# MSP430FR5962 register map
File version: 2.1
CPU: MSP430FR5962 r2p1, little endian, MPU, no FPU, 3 interrupt priority bits
Registers are 16-bit, read-write, reset 0x0 unless marked. A register's access mark holds for its fields unless they carry their own. Offsets are from the block's base; [hi:lo] are bit positions; {n}, {i} and the like mark numbered series; 'fields as' and 'values as' point back to an identical list.

## PJ
Base 0x00000200
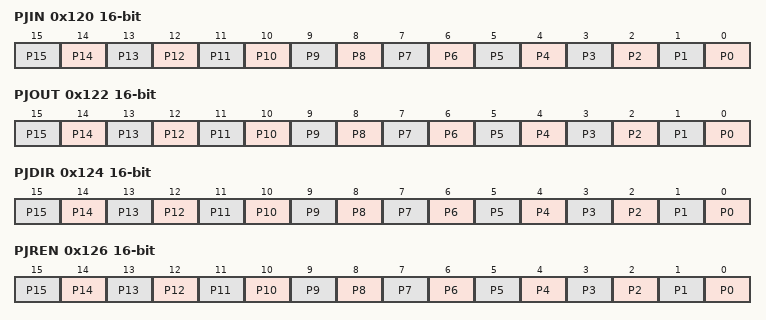
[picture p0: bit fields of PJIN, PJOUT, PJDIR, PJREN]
0x120 PJIN — Port J Input
  [n] P{n} (n=0..15)
0x122 PJOUT — Port J Output
  [n] P{n} (n=0..15)
0x124 PJDIR — Port J Direction
  [n] P{n} (n=0..15)
0x126 PJREN — Port J Resistor Enable
  [n] P{n} (n=0..15)
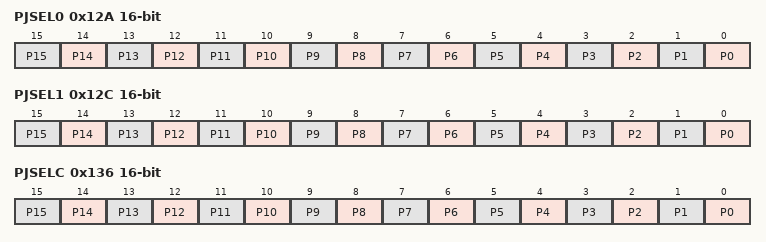
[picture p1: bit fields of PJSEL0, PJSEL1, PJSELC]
0x12A PJSEL0 — Port J Select 0
  [n] P{n} (n=0..15)
0x12C PJSEL1 — Port J Select 1
  [n] P{n} (n=0..15)
0x136 PJSELC — Port J Complement Select
  [n] P{n} (n=0..15)

## DMA
Base 0x00000500
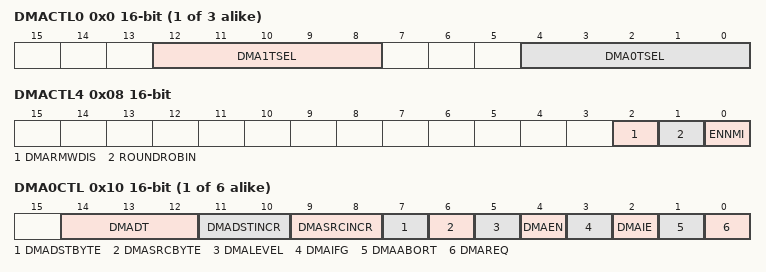
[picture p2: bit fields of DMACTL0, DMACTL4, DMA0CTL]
{0x0+2i} DMACTL{i} (i=0..2) — DMA Control {i}
  [12:8] DMA{2i+1}TSEL — [12:8] DMA trigger select
    {v}=DMA{2i+1}TRIG{v} (v=0..31)
  [4:0] DMA{2i}TSEL — [4:0] DMA trigger select
    {v}=DMA{2i}TRIG{v} (v=0..31)
0x08 DMACTL4 — DMA Control 4
  [2] DMARMWDIS — [2:2] Read-modify-write disable
    0=DMA transfers can occur during read-modify-write CPU operations; 1=DMA transfers inhibited during read-modify-write CPU operations
  [1] ROUNDROBIN — [1:1] Round robin
    0=DMA channel priority is DMA0-DMA1-DMA2 - ... - DMA7; 1=DMA channel priority changes with each transfer
  [0] ENNMI — [0:0] Enable NMI
    0=NMI does not interrupt DMA transfer; 1=NMI interrupts a DMA transfer
0x0E DMAIV — DMA Interrupt Vector
  [15:0] DMAIV — [15:0] DMA interrupt vector value
    0=NONE (No interrupt pending); 2=DMA0IFG (Interrupt Source: DMA channel 0; Interrupt Flag: DMA0IFG; Interrupt Priority: Highest); 4=DMA1IFG (Interrupt Source: DMA channel 1; Interrupt Flag: DMA1IFG); 6=DMA2IFG (Interrupt Source: DMA channel 2; Interrupt Flag: DMA2IFG); 8=DMA3IFG (Interrupt Source: DMA channel 3; Interrupt Flag: DMA3IFG); 10=DMA4IFG (Interrupt Source: DMA channel 4; Interrupt Flag: DMA4IFG); 12=DMA5IFG (Interrupt Source: DMA channel 5; Interrupt Flag: DMA5IFG); 14=DMA6IFG (Interrupt Source: DMA channel 6; Interrupt Flag: DMA6IFG); 16=DMA7IFG (Interrupt Source: DMA channel 7; Interrupt Flag: DMA7IFG; Interrupt Priority: Lowest)
{0x10+0x10*i} DMA{i}CTL (i=0..5) — DMA Channel {i} Control
  [14:12] DMADT — [14:12] DMA transfer mode
    0=Single transfer; 1=Block transfer; 2=Burst-block transfer; 3=Burst-block transfer; 4=Repeated single transfer; 5=Repeated block transfer; 6=Repeated burst-block transfer; 7=Repeated burst-block transfer
  [11:10] DMADSTINCR — [11:10] DMA destination increment
    0=Destination address is unchanged; 1=Destination address is unchanged; 2=Destination address is decremented; 3=Destination address is incremented
  [9:8] DMASRCINCR — [9:8] DMA source increment
    0=Source address is unchanged; 1=Source address is unchanged; 2=Source address is decremented; 3=Source address is incremented
  [7] DMADSTBYTE — [7:7] DMA destination byte
    0=WORD; 1=BYTE
  [6] DMASRCBYTE — [6:6] DMA source byte
    0=WORD; 1=BYTE
  [5] DMALEVEL — [5:5] DMA level
    0=EDGE (Edge sensitive (rising edge)); 1=LEVEL (Level sensitive (high level))
  [4] DMAEN — [4:4] DMA enable
    0=DISABLE (Disabled); 1=ENABLE (Enabled)
  [3] DMAIFG — [3:3] DMA interrupt flag
    0=No interrupt pending; 1=Interrupt pending
  [2] DMAIE — [2:2] DMA interrupt enable
    0=DISABLE (Disabled); 1=ENABLE (Enabled)
  [1] DMAABORT — [1:1] DMA abort
    0=DMA transfer not interrupted; 1=DMA transfer interrupted by NMI
  [0] DMAREQ — [0:0] DMA request
    0=No DMA start; 1=Start DMA
{0x12+0x10*i} DMA{i}SA 20-bit (i=0..5) — DMA Channel {i} Source Address
{0x16+0x10*i} DMA{i}DA 20-bit (i=0..5) — DMA Channel {i} Destination Address
{0x1A+0x10*i} DMA{i}SZ (i=0..5) — DMA Channel {i} Transfer Size

## FRCTL_A
Base 0x00000140
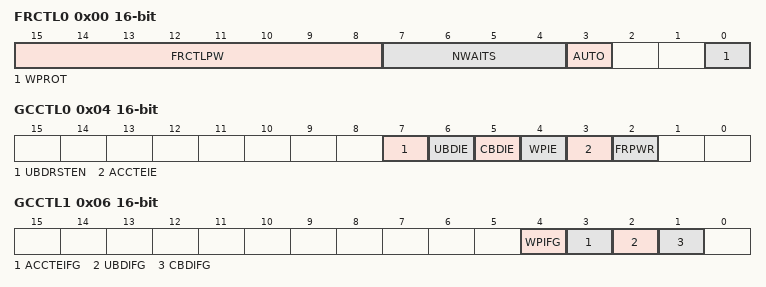
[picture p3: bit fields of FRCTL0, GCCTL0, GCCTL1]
0x00 FRCTL0 — FRAM Controller A Control Register 0
  [15:8] FRCTLPW — [15:8] FRCTLPW password
  [7:4] NWAITS — [7:4] Wait state numbers
    {v}=FRAM wait states: {v} (v=0..15)
  [3] AUTO — [3:3] Enable automatic Wait State Mode
    0=User Wait State Mode. The NWAITS[3:0] is used for the FRAM wait state.; 1=Auto mode. The NWAITS[3:0] is ignored. Wait states are generated automatically by the internal FRAM controller state machine.
  [0] WPROT — [0:0] Write Protection Enable
    0=Disable Write Protection. Write to FRAM memory is allowed.; 1=Enable Write Protection. Write to FRAM memory is not allowed. In case a write access is attempted, the WPIFG (Write Protection Flag) bit will be set.
0x04 GCCTL0 — General Control Register 0
  [7] UBDRSTEN — [7:7] Enable Power Up Clear (PUC) reset for the uncorrectable bit error detection flag (UBDIFG)
    0=PUC not initiated on uncorrectable bit error detection flag; 1=PUC initiated on uncorrectable bit error detection flag. Generates vector in SYSRSTIV. Clear the UBDIE bit.
  [6] UBDIE — [6:6] Enable NMI event for the uncorrectable bit error detection flag (UBDIFG)
    0=Disable NMI for the uncorrectable bit error detection flag (UBDIFG); 1=Enable NMI for the uncorrectable bit error detection flag (UBDIFG). Generates vector in SYSSNIV. Clear the UBDRSTEN bit.
  [5] CBDIE — [5:5] Enable NMI event for the correctable bit error detection flag (CBDIFG)
    0=Disable NMI for the correctable bit error detection flag (CBDIFG); 1=Disable NMI for the correctable bit error detection flag (CBDIFG). Generates vector in SYSSNIV.
  [4] WPIE — [4:4] Enable NMI event for the Write Protection Detection flag (WPIFG)
    0=Disable NMI for the Write Protection Detection flag (WPIFG); 1=Enable NMI for the Write Protection Detection flag (WPIFG). Generates vector in SYSSNIV.
  [3] ACCTEIE — [3:3] Enable NMI event for the Access time error flag (ACCTEIFG)
    0=Disable NMI for the Access time error flag (ACCTEIFG); 1=Enable NMI for the Access time error flag (ACCTEIFG). Generates vector in SYSSNIV.
  [2] FRPWR — [2:2] FRAM Memory Power Control Request
    0=Enable INACTIVE mode; 1=Enable ACTIVE mode
0x06 GCCTL1 — General Control Register 1
  [4] WPIFG — [4:4] Write Protection Detection flag
    0=No interrupt pending; 1=Interrupt pending. Can be cleared by writing '0' or by reading SYSSNIV when it is the highest pending interrupt.
  [3] ACCTEIFG — [3:3] Access time error flag
    values as WPIFG
  [2] UBDIFG — [2:2] FRAM uncorrectable bit error detection flag
    values as WPIFG
  [1] CBDIFG — [1:1] FRAM correctable bit error detection flag
    0=No interrupt is pending; 1=Interrupt pending. Can be cleared by writing '0' or by reading SYSSNIV if it is the highest pending interrupt.
